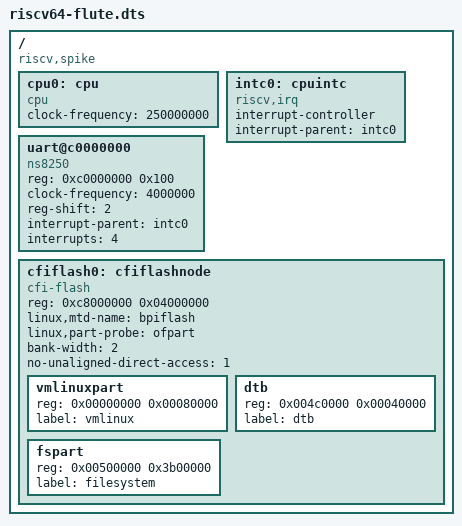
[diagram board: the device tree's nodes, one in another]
/*
 *  Copyright (C) 2016 Bluespec, Inc.
 *
 * This software is licensed under the terms of the GNU General Public
 * License version 2, as published by the Free Software Foundation, and
 * may be copied, distributed, and modified under those terms.
 *
 * This program is distributed in the hope that it will be useful,
 * but WITHOUT ANY WARRANTY; without even the implied warranty of
 * MERCHANTABILITY or FITNESS FOR A PARTICULAR PURPOSE.  See the
 * GNU General Public License for more details.
 */
/dts-v1/;
/ {
	compatible = "riscv,spike";

	#address-cells = <1>;
	#size-cells = <1>;

	cpu0: cpu {
	      compatible = "cpu";
	      clock-frequency = <250000000>;
	};

	intc0: cpuintc {
	       #interrupt-cells = <1>;
	       compatible = "riscv,irq";
	       interrupt-controller;
	       interrupt-parent = <&intc0>; // root interrupt-controller is its own parent
	};

	uart@c0000000 {
		compatible = "ns8250";
		reg = <0xc0000000 0x100>;
		clock-frequency = <4000000>;
		reg-shift = <2>;
		interrupt-parent = <&intc0>;
		interrupts = <4>;
	};

	cfiflash0: cfiflashnode {
		#address-cells = <1>;
		#size-cells = <1>;
		compatible = "cfi-flash";
		reg = <0xc8000000 0x04000000>;
		linux,mtd-name = "bpiflash";
		linux,part-probe = "ofpart";
		bank-width = <2>;
		no-unaligned-direct-access = <1>;
		vmlinuxpart {
			#address-cells = <1>;
			#size-cells = <1>;
			reg = <0x00000000 0x00080000>;
			label = "vmlinux";
		};
		dtb {
			#address-cells = <1>;
			#size-cells = <1>;
			reg = <0x004c0000 0x00040000>;
			label = "dtb";
		};
		fspart {
			#address-cells = <1>;
			#size-cells = <1>;
			reg = <0x00500000 0x3b00000>;
			label = "filesystem";
		};
	};
};
